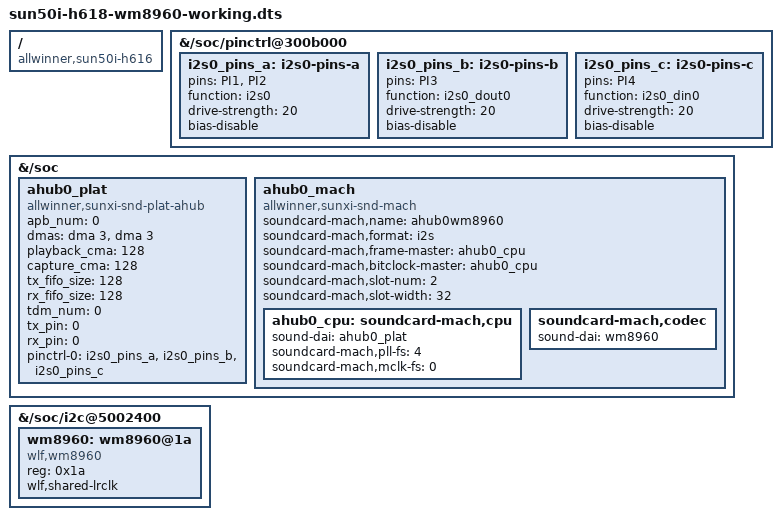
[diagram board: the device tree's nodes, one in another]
/dts-v1/;
/plugin/;

/*
 * WM8960 Audio HAT Overlay for Orange Pi Zero 2W (H618)
 *
 * Applied to the base DTB at install time using fdtoverlay.
 *
 * This overlay:
 * 1. Configures PI1-PI4 pins for I2S0 (BCLK, LRCK, DOUT, DIN)
 * 2. Adds AHUB0 platform device for external I2S
 * 3. Adds AHUB0 machine driver binding WM8960 codec
 * 4. Enables I2C1 (i2c@5002400, Linux bus 2) and adds WM8960 codec at address 0x1a
 */

/ {
    compatible = "allwinner,sun50i-h616";

    fragment@0 {
        target-path = "/soc/pinctrl@300b000";
        __overlay__ {
            i2s0_pins_a: i2s0-pins-a {
                pins = "PI1", "PI2";
                function = "i2s0";
                drive-strength = <20>;
                bias-disable;
            };
            i2s0_pins_b: i2s0-pins-b {
                pins = "PI3";
                function = "i2s0_dout0";
                drive-strength = <20>;
                bias-disable;
            };
            i2s0_pins_c: i2s0-pins-c {
                pins = "PI4";
                function = "i2s0_din0";
                drive-strength = <20>;
                bias-disable;
            };
        };
    };

    fragment@1 {
        target-path = "/soc";
        __overlay__ {
            ahub0_plat: ahub0_plat {
                #sound-dai-cells = <0>;
                compatible = "allwinner,sunxi-snd-plat-ahub";
                apb_num = <0>;
                dmas = <&dma 3>, <&dma 3>;
                dma-names = "tx", "rx";
                playback_cma = <128>;
                capture_cma = <128>;
                tx_fifo_size = <128>;
                rx_fifo_size = <128>;
                tdm_num = <0>;
                tx_pin = <0>;
                rx_pin = <0>;
                pinctrl-names = "default";
                pinctrl-0 = <&i2s0_pins_a>, <&i2s0_pins_b>, <&i2s0_pins_c>;
                status = "okay";
            };

            ahub0_mach {
                compatible = "allwinner,sunxi-snd-mach";
                soundcard-mach,name = "ahub0wm8960";
                soundcard-mach,format = "i2s";
                soundcard-mach,frame-master = <&ahub0_cpu>;
                soundcard-mach,bitclock-master = <&ahub0_cpu>;
                soundcard-mach,slot-num = <2>;
                soundcard-mach,slot-width = <32>;
                status = "okay";

                ahub0_cpu: soundcard-mach,cpu {
                    sound-dai = <&ahub0_plat>;
                    soundcard-mach,pll-fs = <4>;
                    soundcard-mach,mclk-fs = <0>;
                };

                soundcard-mach,codec {
                    sound-dai = <&wm8960>;
                };
            };
        };
    };

    fragment@2 {
        target-path = "/soc/i2c@5002400";
        __overlay__ {
            status = "okay";
            #address-cells = <1>;
            #size-cells = <0>;

            wm8960: wm8960@1a {
                compatible = "wlf,wm8960";
                reg = <0x1a>;
                #sound-dai-cells = <0>;
                wlf,shared-lrclk;
                status = "okay";
            };
        };
    };
};
